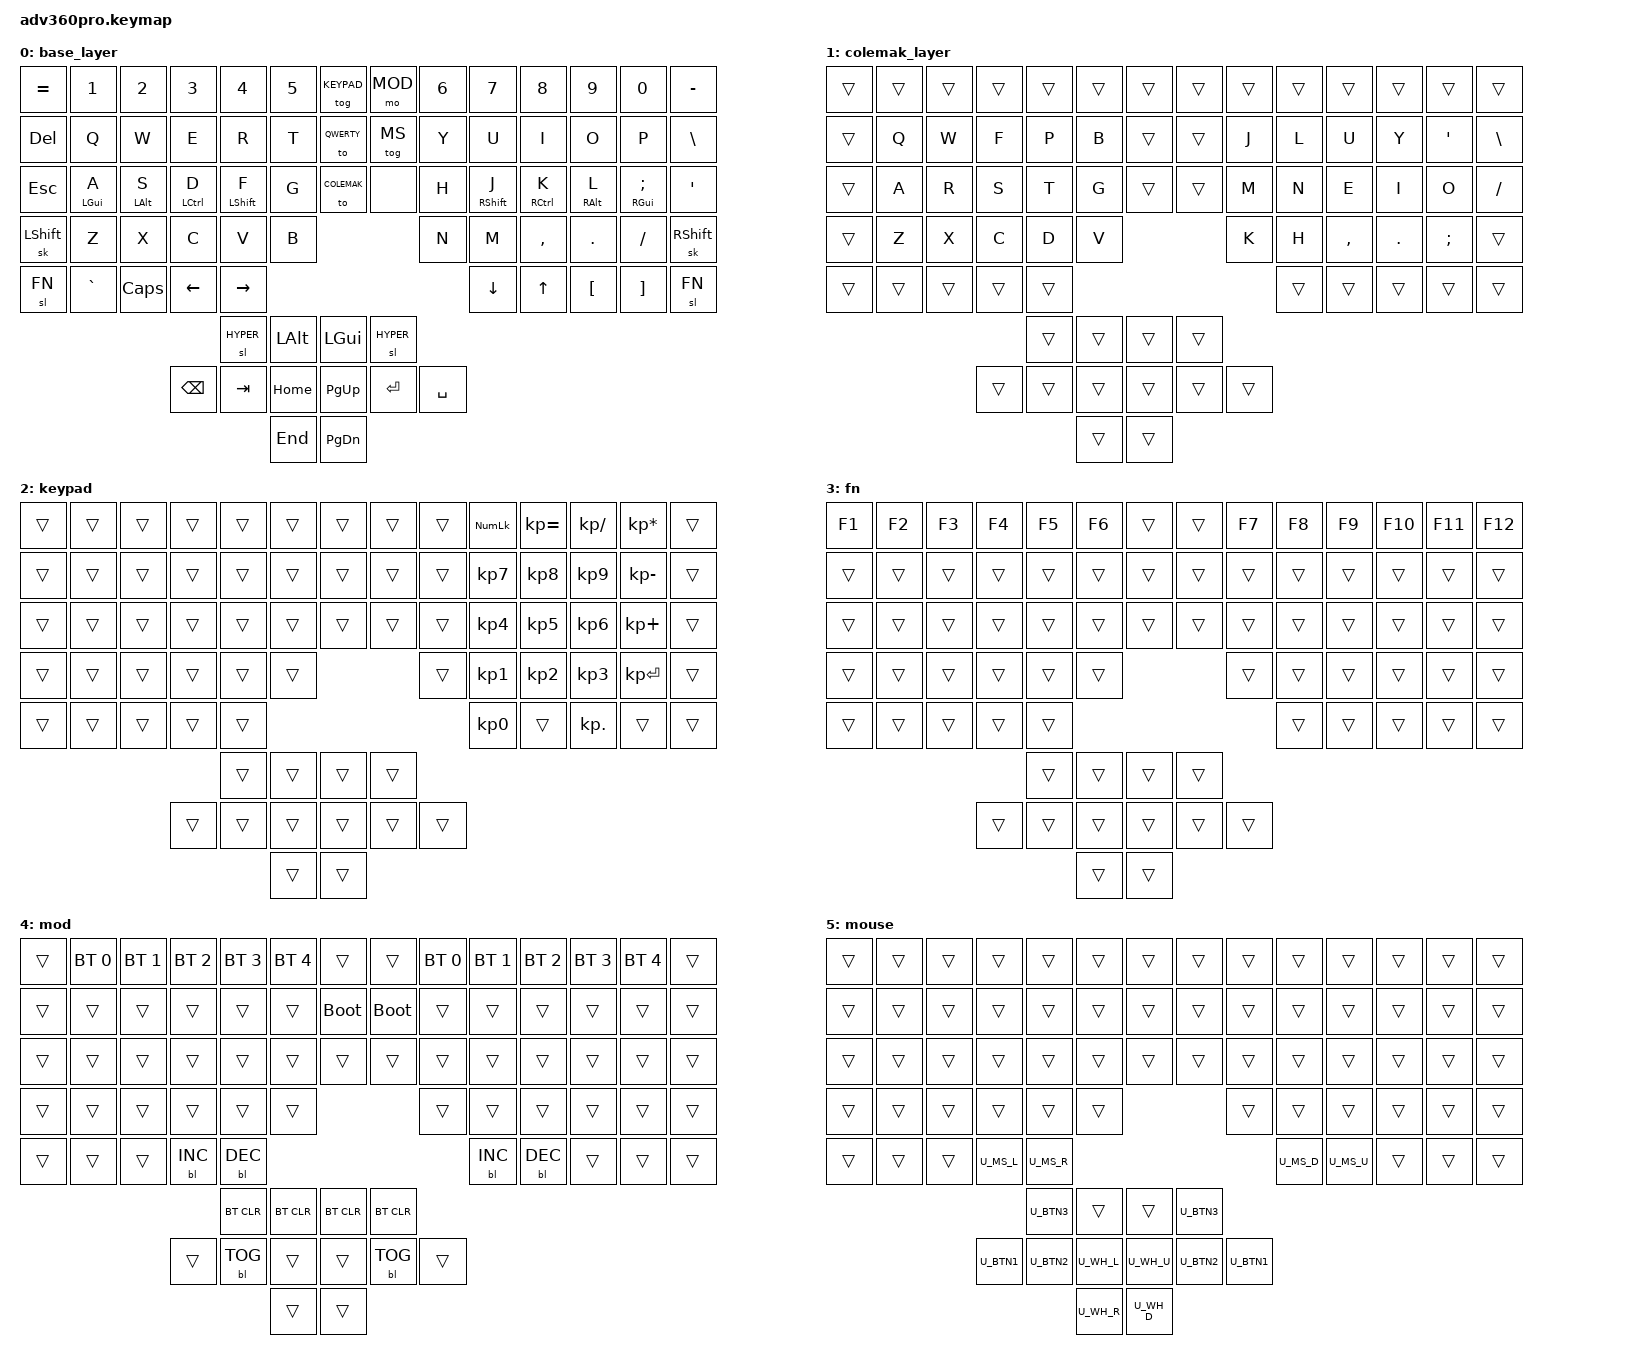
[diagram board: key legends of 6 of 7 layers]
/* source keypos definitions */
#include "../zmk-nodefree-config/keypos_def/keypos_adv360.h"


/* activate bluetooth */
#define CONFIG_WIRELESS 1

#include <behaviors.dtsi>
#include <dt-bindings/zmk/keys.h>
#include <dt-bindings/zmk/bt.h>
#include <dt-bindings/zmk/outputs.h>
#include <dt-bindings/zmk/rgb.h>
#include <dt-bindings/zmk/backlight.h>
#

/* definitions for mouse layer */
#include "mouse.dtsi"

#define ___ &trans

#define QWERTY 0
#define COLEMAK 1
#define KEYPAD 2
#define FN 3
#define MOD 4
#define MS 5
#define HYPER 6

#define KEYS_L LN5 LN4 LN3 LN2 LN1 LN0 LT5 LT4 LT3 LT2 LT1 LT0 LM5 LM4 LM3 LM2 LM1 LM0 LB5 LB4 LB3 LB2 LB1 LB0 57 58
#define KEYS_R RN0 RN1 RN2 RN3 RN4 RN5 RT0 RT1 RT2 RT3 RT4 RT5 RM0 RM1 RM2 RM3 RM4 RM5 RB0 RB1 RB2 RB3 RB4 RB5 59 60
#define KEYS_T LH2 LH1 LH0 RH0 RH1 RH2

#define HM_TAPPING_TERM 280
#define HM_TAPPING_TERM_FAST 150


/ {
    /* remove unused keys from layout and move thumb cluster to bottom */
    chosen {
        zmk,matrix_transform = &urobs_transform;
    };
    behaviors {

        // Positional Homerow mods
        // Homerow mods that prevent accidental activations when rolling keys,
        // such as when typing `st` or `ne` on colemak-dh layouts or `as` on
        // qwerty.
        //
        // Works by only allowing a mod to activate within tapping-term if
        // it's on the opposite side of the keyboard or on the same side thumb
        // keys.

        // Further optimization using urob's timerless homerow mods method:
        // https://github.com/urob/zmk-config#timeless-homerow-mods
        // Positional Homerow mods for shift

        // Use faster tapping term and disable some features that may
        // cause false negatives.
    homey_left: home_row_mods_left_hand {
        compatible = "zmk,behavior-hold-tap";
        flavor = "balanced";
        label = "HOME_ROW_MODS_LEFT_HAND";
        #binding-cells = <2>;
        bindings = <&kp>, <&kp>;
        hold-trigger-key-positions = <KEYS_R KEYS_T>;
        hold-trigger-on-release; // FIXME: needs ZMK 3.2
        tapping-term-ms = <250>;
        quick-tap-ms = <160>;
        global-quick-tap; // with typing streak
    };

    homey_right: home_row_mods_right_hand {
        compatible = "zmk,behavior-hold-tap";
        flavor = "balanced";
        label = "HOME_ROW_MODS_RIGHT_HAND";
        #binding-cells = <2>;
        bindings = <&kp>, <&kp>;
        hold-trigger-key-positions = <KEYS_L KEYS_T>;
        hold-trigger-on-release; // FIXME: needs ZMK 3.2
        tapping-term-ms = <250>;
        quick-tap-ms = <160>;
        global-quick-tap; // with typing streak
    };
    hm_shift_l: hm_shift_l {
        compatible = "zmk,behavior-hold-tap";
        label = "HOMEROW_MODS_FAST_LEFT";
        #binding-cells = <2>;
        bindings = <&kp>, <&kp>;

        flavor = "balanced";
        tapping-term-ms = <150>;
        quick_tap_ms = <175>;
        //global-quick-tap;
        //global-quick-tap-ms = <150>;         // requires PR #1387
        hold-trigger-key-positions = <KEYS_R KEYS_T>;
        //hold-trigger-on-release;             // requires PR #1423
    };

    hm_shift_r: hm_shift_r {
        compatible = "zmk,behavior-hold-tap";
        label = "HOMEROW_MODS_FAST_RIGHT";
        #binding-cells = <2>;
        bindings = <&kp>, <&kp>;

        flavor = "balanced";
        tapping-term-ms = <150>;
        quick_tap_ms = <175>;
        //global-quick-tap;
        //global-quick-tap-ms = <150>;         // requires PR #1387
        hold-trigger-key-positions = <KEYS_L KEYS_T>;
        //hold-trigger-on-release;             // requires PR #1423
    };
    };
    macros {
        term_fscreen: term_fscreen {
            label = "term_fscreen";
            compatible = "zmk,behavior-macro";
            #binding-cells = <0>;
            bindings = <&kp LC(LSHFT)>, <&kp Z>;
        };
    };
    keymap {
        compatible = "zmk,keymap";

        base_layer {
            bindings = <
                &kp EQUAL &kp N1      &kp N2       &kp N3         &kp N4        &kp N5      &tog KEYPAD    &mo MOD &kp N6    &kp N7        &kp N8        &kp N9        &kp N0          &kp MINUS
                &kp DEL   &kp Q       &kp W        &kp E          &kp R         &kp T       &to QWERTY     &tog MS &kp Y     &kp U         &kp I         &kp O         &kp P           &kp BSLH
                &kp ESC   &homey_left LGUI A   &homey_left LALT S &homey_left LCTRL D   &hm_shift_l LSHFT F &kp G   &to COLEMAK    &none   &kp H     &hm_shift_r RSHFT J &homey_right RCTRL K  &homey_right RALT L  &homey_right RGUI SEMI &kp SQT
                &sk LSHFT &kp Z       &kp X        &kp C          &kp V         &kp B                              &kp N     &kp M         &kp COMMA     &kp DOT       &kp FSLH        &sk RSHFT
                &sl FN    &kp GRAVE   &kp CAPS     &kp LEFT       &kp RIGHT                                                  &kp DOWN      &kp UP        &kp LBKT      &kp RBKT        &sl FN
                                                                  &sl HYPER &kp LALT  &kp LGUI  &sl HYPER
                                                        &kp BSPC  &kp TAB   &kp HOME  &kp PG_UP &kp ENTER &kp SPACE
                                                                            &kp END   &kp PG_DN
            >;
        };

        colemak_layer {
            bindings = <
                ___       ___       ___       ___       ___       ___                 ___   ___      ___       ___           ___          ___          ___       ___
                ___       &kp Q     &kp W     &kp F     &kp P     &kp B               ___   ___      &kp J     &kp L         &kp U        &kp Y        &kp SQT   &kp BSLH
                ___       &kp A     &kp R     &kp S     &kp T     &kp G ___   ___                    &kp M     &kp N         &kp E        &kp I &kp O  &kp FSLH
                ___       &kp Z     &kp X     &kp C     &kp D     &kp V                              &kp K     &kp H         &kp COMMA    &kp DOT      &kp SEMI  ___
                ___       ___       ___       ___       ___                                                    ___           ___          ___          ___       ___
                                                                  ___       ___            ___       ___
                                                        ___       ___       ___            ___       ___       ___
                                                                            ___            ___
            >;
        };

        keypad {
            bindings = <
                ___       ___       ___       ___       ___       ___       ___            ___       ___       &kp KP_NUM &kp KP_EQUAL &kp KP_DIVIDE &kp KP_MULTIPLY ___
                ___       ___       ___       ___       ___       ___       ___            ___       ___       &kp KP_N7  &kp KP_N8    &kp KP_N9     &kp KP_MINUS    ___
                ___       ___       ___       ___       ___       ___       ___            ___       ___       &kp KP_N4  &kp KP_N5    &kp KP_N6     &kp KP_PLUS     ___
                ___       ___       ___       ___       ___       ___                                ___       &kp KP_N1  &kp KP_N2    &kp KP_N3     &kp KP_ENTER    ___
                ___       ___       ___       ___       ___                                                    &kp KP_N0  ___          &kp KP_DOT    ___             ___
                                                                  ___       ___            ___       ___
                                                        ___       ___       ___            ___       ___       ___
                                                                            ___            ___
            >;
        };

        fn {
            bindings = <
                &kp F1    &kp F2    &kp F3    &kp F4    &kp F5    &kp F6    ___            ___       &kp F7    &kp F8    &kp F9    &kp F10   &kp F11   &kp F12
                ___       ___       ___       ___       ___       ___       ___            ___       ___       ___       ___       ___       ___       ___
                ___       ___       ___       ___       ___       ___       ___            ___       ___       ___       ___       ___       ___       ___
                ___       ___       ___       ___       ___       ___                                ___       ___       ___       ___       ___       ___
                ___       ___       ___       ___       ___                                                    ___       ___       ___       ___       ___
                                                                  ___       ___            ___       ___
                                                        ___       ___       ___            ___       ___       ___
                                                                            ___            ___
            >;
        };

        mod {
            bindings = <
                ___       &bt BT_SEL 0 &bt BT_SEL 1 &bt BT_SEL 2 &bt BT_SEL 3 &bt BT_SEL 4 ___              ___         &bt BT_SEL 0 &bt BT_SEL 1     &bt BT_SEL 2 &bt BT_SEL 3 &bt BT_SEL 4 ___
                ___       ___          ___          ___          ___          ___          &bootloader      &bootloader ___          ___              ___          ___          ___          ___
                ___       ___          ___          ___          ___          ___          ___              ___         ___          ___              ___          ___          ___          ___
                ___       ___          ___          ___          ___          ___                                       ___          ___              ___          ___          ___          ___
                ___       ___          ___          &bl BL_INC   &bl BL_DEC                                                          &bl BL_INC       &bl BL_DEC   ___          ___          ___
                                                                              &bt BT_CLR   &bt BT_CLR       &bt BT_CLR  &bt BT_CLR
                                                                 ___          &bl BL_TOG   ___              ___         &bl BL_TOG   ___
                                                                                           ___              ___
            >;
        };

        mouse {
            bindings = <
                ___       ___       ___       ___       ___       ___       ___            ___       ___       ___       ___       ___       ___       ___
                ___       ___       ___       ___       ___       ___       ___            ___       ___       ___       ___       ___       ___       ___
                ___       ___       ___       ___       ___       ___       ___            ___       ___       ___       ___       ___       ___       ___
                ___       ___       ___       ___       ___       ___                                ___       ___       ___       ___       ___       ___
                ___       ___       ___       U_MS_L    U_MS_R                                                 U_MS_D    U_MS_U    ___       ___       ___
                                                                  U_BTN3    ___            ___       U_BTN3
                                                        U_BTN1    U_BTN2    U_WH_L         U_WH_U    U_BTN2    U_BTN1
                                                                            U_WH_R         U_WH_D
            >;
        };

        hyper {
            bindings = <
                ___    ___                  ___     ___                  ___                ___       ___        ___       ___       ___       ___       ___       ___       ___
                ___    ___                  ___     ___                  ___                ___       ___        ___       ___       ___       ___       ___       ___       ___
                ___    ___                  &kp LC(LS(LA(PRCNT)))     &kp LC(LS(LA(DQT)))                  ___                ___       ___        ___       &kp LC(LS(LEFT)) &kp LC(LS(DOWN)) &kp LC(LS(UP)) &kp LC(LS(RIGHT)) ___       ___
                ___    &kp LC(LS(Z))   ___     &kp LC(LS(C))        &kp LC(LS(V))      ___                            ___       ___       ___       ___       ___       ___
                ___    ___                  ___     &kp LG(LC(LEFT))     &kp LG(LC(RIGHT))                                           ___       ___       ___       ___       ___
                                                                  ___             ___            ___       ___
                                                        &kp LC(B)       &kp LC(LA(TAB)) ___            ___       ___       ___
                                                                                  ___            ___
            >;
        };
    };

};
